# ATmega64HVE2 register map
Vendor: Atmel; File version: 1.0
CPU: other r0p0, little endian, no MPU, no FPU, 4 interrupt priority bits
Registers are 8-bit, read-write, reset 0x0 unless marked. A register's access mark holds for its fields unless they carry their own. Offsets are from the block's base; [hi:lo] are bit positions; {n}, {i} and the like mark numbered series.

## ADC — Analog-to-Digital Converter
Base 0x000000E0
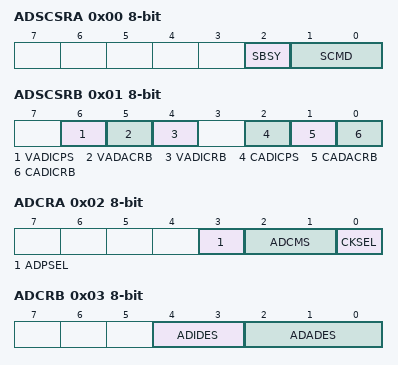
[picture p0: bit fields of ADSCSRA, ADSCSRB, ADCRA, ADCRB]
0x00 ADSCSRA — ADC Synchronization Control and Status Register
  [2] SBSY — Synchronization Busy
  [1:0] SCMD — Synchronization Command
    1=Reset and Synchronize; 2=Synchronize on next Instantaneous Conversion; 3=Synchronize on next Accumulated Conversion
0x01 ADSCSRB — ADC Synchronization Control and Status Register
  [6] VADICPS — V-ADC Instantaneous Conversion Polarity Status
  [5] VADACRB — VADAC Data Read Out Busy
  [4] VADICRB — VADIC Data Read Out Busy
  [2] CADICPS — C-ADC Instantaneous Conversion Polarity Status
  [1] CADACRB — CADAC Data Read Out Busy
  [0] CADICRB — CADIC Data Read Out Busy
0x02 ADCRA — ADC Control Register A
  [3] ADPSEL — ADC Polarity Select
  [2:1] ADCMS — C-ADC Chopper Mode Select
    0=Chopping Disabled; 1=Automatic Fast Chopping; 2=Automatic Slow Chopping; 3=Software Polarity Control
  [0] CKSEL — Sampling Clock Select
    0=PLL (512kHz output) as sampling clock; 1=Slow RC Oscillator as sampling clock
0x03 ADCRB — ADC Control Register B
  [4:3] ADIDES — Instantaneous Decimation Ratio Select
    0=512; 1=256; 2=128; 3=64
  [2:0] ADADES — Accumulated Decimation Ratio Select
    0=512; 1=256; 2=128; 3=64; 4=32; 5=16; 6=8; 7=4
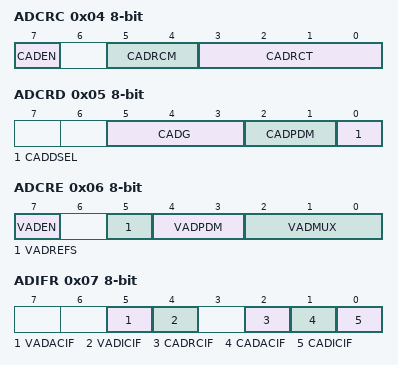
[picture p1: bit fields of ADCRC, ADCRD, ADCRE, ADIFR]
0x04 ADCRC — ADC Control Register B
  [7] CADEN — C-ADC Enable
  [5:4] CADRCM — C-ADC Regular Current Comparator Mode
    0=Comparator Disabled; 1=Comparator Enabled. Regular Current Counter counts up if Accumulated Current is above threshold and is reset if Accumulated Current is below threshold.; 2=Comparator Enabled. Regular Current Counter counts up if Accumulated Current is above threshold and down if Accumulated Current is below threshold.
  [3:0] CADRCT — C-ADC Regular Current Count Threshold
    {v}={v+1} (v=0..15)
0x05 ADCRD — ADC Control Register D
  [5:3] CADG — C-ADC Gain
    0=4x; 1=8x; 2=16x; 3=32x; 4=64x; 5=128x; 6=256x
  [2:1] CADPDM — C-ADC Pin Diagnostics Mode
    0=No current source is enabled; 1=Current source on PI pin enabled; 2=Current source on NI pin enabled; 3=Current source on both PI/NI pins enabled
  [0] CADDSEL — C-ADC Diagnostics Channel Select
0x06 ADCRE — ADC Control Register E
  [7] VADEN — V-ADC Enable
  [5] VADREFS — V-ADC Reference Select
    0=VREF as reference; 1=AVDD/3 as reference (for diagnosis purpose)
  [4:3] VADPDM — V-ADC Pin Diagnostics Mode
    0=No current source is enabled; 1=Current source on PV pin enabled; 2=Current source on NV pin enabled; 3=Current source on both PV/NV pins enabled
  [2:0] VADMUX — V-ADC Channel Select
    0=PV - NV; 1=ADC0 - SGND; 2=ADC1 - SGND; 3=VTEMP - GND; 4=DIAGNOSIS - GND (VREF/TBD)
0x07 ADIFR — ADC Interrupt Flag Register
  [5] VADACIF — V-ADC Accumulated Voltage Interrupt Flag
  [4] VADICIF — V-DAC Instantaneous Voltage Interrupt Flag
  [2] CADRCIF — C-ADC Regulator Current Interrupt Flag
  [1] CADACIF — C-ADC Accumulated Current Interrupt Flag
  [0] CADICIF — C-ADC Instantaneous Current Interrupt Flag
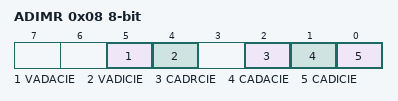
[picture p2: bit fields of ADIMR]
0x08 ADIMR — ADC Interrupt Mask Register
  [5] VADACIE — V-ADC Accumulated Voltage Interrupt Enable
  [4] VADICIE — V-DAC Instantaneous Voltage Interrupt Enable
  [2] CADRCIE — C-ADC Regulator Current Interrupt Enable
  [1] CADACIE — C-ADC Accumulated Current Interrupt Enable
  [0] CADICIE — C-ADC Instantaneous Current Interrupt Enable
0x09 CADRCL 16-bit (reset mask 0xFF) — CC-ADC Regulator Current Comparator Threshold Level
0x0B CADIC 16-bit (reset mask 0xFF) — C-ADC Instantaneous Conversion Result
{0xD+i} CADAC{i} (i=0..3) — C-ADC Accumulated Conversion Result
0x11 VADIC 16-bit (reset mask 0xFF) — V-ADC Instantaneous Conversion Result
{0x13+i} VADAC{i} (i=0..3) — V-ADC Accumulated Conversion Result
